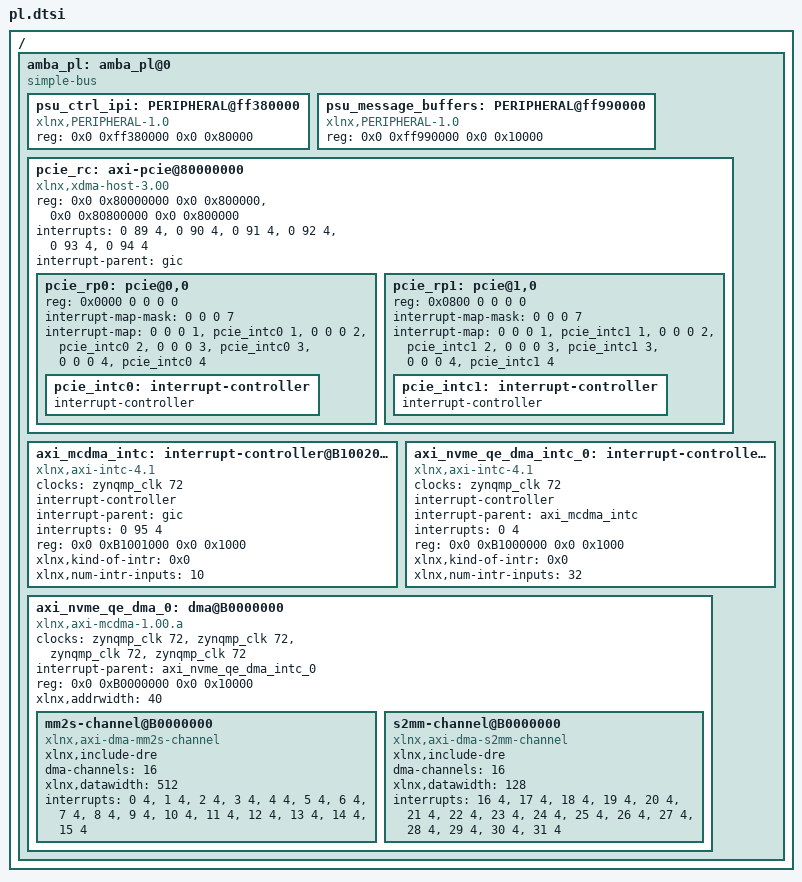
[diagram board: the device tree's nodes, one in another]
/*
 * CAUTION: This file is automatically generated by Xilinx.
 * Version: HSI 2019.1
 * Today is: Sat Jun  6 20:32:13 2020
 */

/ {
	amba_pl: amba_pl@0 {
		#address-cells = <2>;
		#size-cells = <2>;
		compatible = "simple-bus";
		ranges ;
		psu_ctrl_ipi: PERIPHERAL@ff380000 {
			/* This is a place holder node for a custom IP, user may need to update the entries */
			compatible = "xlnx,PERIPHERAL-1.0";
			reg = <0x0 0xff380000 0x0 0x80000>;
		};
		psu_message_buffers: PERIPHERAL@ff990000 {
			/* This is a place holder node for a custom IP, user may need to update the entries */
			compatible = "xlnx,PERIPHERAL-1.0";
			reg = <0x0 0xff990000 0x0 0x10000>;
		};

                pcie_rc: axi-pcie@80000000 {
			compatible = "xlnx,xdma-host-3.00";
			device_type = "pci";
			reg = <0x0 0x80000000 0x0 0x800000>, /*Root port 0*/
			    <0x0 0x80800000 0x0 0x800000>; /*Root port 1*/
			reg-names = "rp0", "rp1";
			#address-cells = <3>;
			#size-cells = <2>;
			ranges = <0x02000000 0x0 0xA0000000 0x0 0xA0000000 0x0 0x200000>;
			#interrupt-cells = <1>;
			interrupts = <0 89 4>,  /*Root port 0 INTx*/
				   <0 90 4>,  /*Root port 0 MSI0*/
				   <0 91 4>,  /*Root port 0 MSI1*/
				   <0 92 4>,  /*Root port 1 INTx*/
				   <0 93 4>,  /*Root port 1 MSI0*/
				   <0 94 4>;  /*Root port 1 MSI1*/
			interrupt-parent = <&gic>;

			pcie_rp0: pcie@0,0 {
				device_type = "pci";
				reg = <0x0000 0 0 0 0>;
				#address-cells = <3>;
				#size-cells = <2>;
				ranges;
				#interrupt-cells = <1>;
				interrupt-map-mask = <0 0 0 7>;
				interrupt-map = <0 0 0 1 &pcie_intc0 1>,
					<0 0 0 2 &pcie_intc0 2>,
					<0 0 0 3 &pcie_intc0 3>,
					<0 0 0 4 &pcie_intc0 4>;
				pcie_intc0: interrupt-controller {
					interrupt-controller;
					#address-cells = <0>;
					#interrupt-cells = <1>;
				};
			};

			pcie_rp1: pcie@1,0 {
				device_type = "pci";
				reg = <0x0800 0 0 0 0>;
				#address-cells = <3>;
				#size-cells = <2>;
				ranges;
				#interrupt-cells = <1>;
				interrupt-map-mask = <0 0 0 7>;
				interrupt-map = <0 0 0 1 &pcie_intc1 1>,
					<0 0 0 2 &pcie_intc1 2>,
					<0 0 0 3 &pcie_intc1 3>,
					<0 0 0 4 &pcie_intc1 4>;
				pcie_intc1: interrupt-controller {
					interrupt-controller;
					#address-cells = <0>;
					#interrupt-cells = <1>;
				};
			};
		};

		axi_mcdma_intc: interrupt-controller@B1002000 {
			#interrupt-cells = <2>;
			clock-names = "s_axi_aclk";
			clocks = <&zynqmp_clk 72>;
			compatible = "xlnx,axi-intc-4.1", "xlnx,xps-intc-1.00.a";
			interrupt-controller ;
			interrupt-names = "irq";
			interrupt-parent = <&gic>;
			interrupts = <0 95 4>;
			reg = <0x0 0xB1001000 0x0 0x1000>;
			xlnx,kind-of-intr = <0x0>;
			xlnx,num-intr-inputs = <10>;
		};

		axi_nvme_qe_dma_intc_0: interrupt-controller@B1000000 {
			#interrupt-cells = <2>;
			clock-names = "s_axi_aclk";
			clocks = <&zynqmp_clk 72>;
			compatible = "xlnx,axi-intc-4.1", "xlnx,xps-intc-1.00.a";
			interrupt-controller ;
			interrupt-names = "irq";
			interrupt-parent = <&axi_mcdma_intc>;
			interrupts = <0 4>;
			reg = <0x0 0xB1000000 0x0 0x1000>;
			xlnx,kind-of-intr = <0x0>;
			xlnx,num-intr-inputs = <32>;
		};

		axi_nvme_qe_dma_0: dma@B0000000 {
			#dma-cells = <1>;
			compatible = "xlnx,axi-mcdma-1.00.a";
			clock-names = "s_axi_lite_aclk", "m_axi_sg_aclk", "m_axi_mm2s_aclk", "m_axi_s2mm_aclk";
			clocks = <&zynqmp_clk 72>, <&zynqmp_clk 72>, <&zynqmp_clk 72>, <&zynqmp_clk 72>;
			interrupt-parent = <&axi_nvme_qe_dma_intc_0>;
			reg = <0x0 0xB0000000 0x0 0x10000>;
			xlnx,addrwidth = <40>;
			mm2s-channel@B0000000 {
				compatible = "xlnx,axi-dma-mm2s-channel";
				xlnx,include-dre ;
				dma-channels = <16>;
				xlnx,datawidth = <512>;
				interrupts = <0 4>, <1 4>, <2 4>, <3 4>,
					     <4 4>, <5 4>, <6 4>, <7 4>,
					     <8 4>, <9 4>, <10 4>, <11 4>,
					     <12 4>, <13 4>, <14 4>, <15 4>;
			};
			s2mm-channel@B0000000 {
				compatible = "xlnx,axi-dma-s2mm-channel";
				xlnx,include-dre ;
				dma-channels = <16>;
				xlnx,datawidth = <128>;
				interrupts = <16 4>, <17 4>, <18 4>, <19 4>,
					     <20 4>, <21 4>, <22 4>, <23 4>,
					     <24 4>, <25 4>, <26 4>, <27 4>,
					     <28 4>, <29 4>, <30 4>, <31 4>;
			};
		};
	};
};
